# moonlight_application register map
Vendor: Nordic Semiconductor; Series: lumos; File version: 1
CPU: CM33 r0p4, little endian, MPU, FPU, 3 interrupt priority bits, 176 interrupts, 4 SAU regions
Registers are 32-bit, read-write, reset 0x0 unless marked. A register's access mark holds for its fields unless they carry their own. Offsets are from the block's base; [hi:lo] are bit positions; lines under a group give offsets from that group; {n}, {i} and the like mark numbered series; 'fields as' and 'values as' point back to an identical list.

## GLOBAL_UICR_S — User Information Configuration Registers
Base 0x00FFD000
{0x0+0x20*i} APPROTECT[{i}] (i=0..0) group — Access Port Protection Registers
  0x00 PROTECT0 rw-once reset 0xFFFFFFFF — Description cluster: Access port protection
    [31:0] PALL
      0x50FA50FA=Protected (Blocks debugger read/write access to all CPU registers and memory mapped addresses, and locks TAMPC PROTECT.DOMAIN DBGEN and NIDEN signal protectors.)
  {0x4+4j} UNPROTECT0[{j}] (j=0..2) rw-once reset 0x50FA50FA — Description collection: Access port protection register o
    [31:0] PALL
      0x50FA50FA=Unprotected (TAMPC is locked for all other values than Unprotected.)
  {0x10+4j} UNPROTECT1[{j}] (j=0..2) rw-once reset 0x50FA50FA — Description collection: Access port protection
    fields as APPROTECT[0].UNPROTECT0[0]
  0x1C PROTECT1 rw-once reset 0xFFFFFFFF — Description cluster: Access port protection register
    fields as APPROTECT[0].PROTECT0
{0x20+0x20*i} SECUREAPPROTECT[{i}] (i=0..0) group — Access Port Protection Registers
  0x00 PROTECT0 rw-once reset 0xFFFFFFFF — Description cluster: Access port protection
    [31:0] PALL
      0x50FA50FA=Protected (Blocks debugger read/write access to all CPU registers and memory mapped addresses, and locks TAMPC PROTECT.DOMAIN SPIDEN and SPNIDEN signal protectors.)
  {0x4+4j} UNPROTECT0[{j}] (j=0..2) rw-once reset 0x50FA50FA — Description collection: Access port protection register o
    fields as APPROTECT[0].UNPROTECT0[0]
  {0x10+4j} UNPROTECT1[{j}] (j=0..2) rw-once reset 0x50FA50FA — Description collection: Access port protection
    fields as APPROTECT[0].UNPROTECT0[0]
  0x1C PROTECT1 rw-once reset 0xFFFFFFFF — Description cluster: Access port protection register
    fields as SECUREAPPROTECT[0].PROTECT0
{0x40+0x20*i} AUXAPPROTECT[{i}] (i=0..0) group — Access Port Protection Registers
  0x00 PROTECT0 rw-once reset 0xFFFFFFFF — Description cluster: Access port protection
    [31:0] PALL
      0x50FA50FA=Protected (Blocks debugger read/write access to all CPU registers and memory mapped addresses, and locks TAMPC PROTECT.AP[0] DBGEN signal protector.)
  {0x4+4j} UNPROTECT0[{j}] (j=0..2) rw-once reset 0x50FA50FA — Description collection: Access port protection register o
    fields as APPROTECT[0].UNPROTECT0[0]
  {0x10+4j} UNPROTECT1[{j}] (j=0..2) rw-once reset 0x50FA50FA — Description collection: Access port protection
    fields as APPROTECT[0].UNPROTECT0[0]
  0x1C PROTECT1 rw-once reset 0xFFFFFFFF — Description cluster: Access port protection register
    fields as AUXAPPROTECT[0].PROTECT0
{0x60+0x20*i} ERASEPROTECT[{i}] (i=0..0) group — Erase Protection Registers
  {0x4+4j} PROTECT0[{j}] (j=0..2) rw-once reset 0x50FA50FA — Description collection: Erase protection register o
    [31:0] PALL
      0x50FA50FA=Protected, the device cannot be erased and TAMPC PROTECT.ERASEPROTECT signal protector is locked
  {0x10+4j} PROTECT1[{j}] (j=0..2) rw-once reset 0x50FA50FA — Description collection: Erase protection register o
    fields as ERASEPROTECT[0].PROTECT0[0]
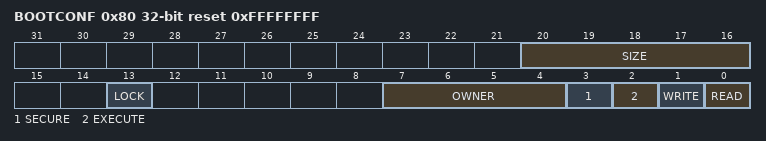
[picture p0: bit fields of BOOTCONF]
0x80 BOOTCONF rw-once reset 0xFFFFFFFF — Immutable boot region configuration.
  [20:16] SIZE — Immutable boot region size
  [13] LOCK — Enable lock of configuration register
    0=Disabled (Lock is disabled, and the RRAMC region configuration registers for the immutable boot region are writable.); 1=Enabled (Lock is enabled, and the RRAMC configuration registers for the immutable boot region are read-only.)
  [7:4] OWNER — Owner ID configuration
    0=NONE (Ownership is not enforced); 1=APP (Application core (all but KMU)); 2=KMU (Key management unit (KMU))
  [3] SECURE — Secure access enable
    0=NotAllowed (Secure access to the region is allowed); 1=Allowed (Secure access to the region is not allowed)
  [2] EXECUTE — Execute access enable
    0=NotAllowed (Executing code from the region is allowed); 1=Allowed (Executing code from the region is not allowed)
  [1] WRITE — Write access enable
    0=NotAllowed (Writing to the region is not allowed); 1=Allowed (Writing to the region is allowed)
  [0] READ — Read access enable
    0=NotAllowed (Reading from the region is not allowed); 1=Allowed (Reading from the region is allowed)
0x84 BOOTCONFKEY rw-once reset 0x50FA50FA — Static key for BOOTCONF anti-tamper protection
0x200 USER group — Unspecified
  0x00 ROT group — Assets installed to establish initial Root of Trust in the device.
    {0x0+0x2C*k} PUBKEY[{k}] (k=0..3) group — Unspecified
      {0x0+4l} DIGEST[{l}] (l=0..7) rw-once reset 0xFFFFFFFF — Description collection: First 256 bits of SHA2-512 digest over RoT public key generation [n].
        [31:0] VALUE — Value for word [o] in the key digest [n].
      {0x20+4l} REVOKE[{l}] (l=0..2) rw-once reset 0xFFFFFFFF — Description collection: Revocation status for RoT public key generation [n].
        [31:0] STATUS — Revocation status.
          0xFFFFFFFF=NotRevoked (Key not revoked.)
    {0xB0+0x2C*k} AUTHOPKEY[{k}] (k=0..3) group — Unspecified
      {0x0+4l} DIGEST[{l}] (l=0..7) rw-once reset 0xFFFFFFFF — Description collection: First 256 bits of SHA2-512 digest over RoT authenticated operation public key generation [n].
        [31:0] VALUE — Value for word [o] in the key digest [n].
      {0x20+4l} REVOKE[{l}] (l=0..2) rw-once reset 0xFFFFFFFF — Description collection: Revocation status for RoT authenticated operation public key generation [n].
        fields as USER.ROT.PUBKEY[0].REVOKE[0]
{0x500+4i} OTP[{i}] (i=0..319) rw-once reset 0xFFFFFFFF — Description collection: One time programmable memory
  [31:0] OTP — OTP word
